# GD32F5xx register map
File version: 1.0
CPU: CM33 r0p1, little endian, MPU, FPU, 4 interrupt priority bits
Registers are 32-bit, read-write, reset 0x0 unless marked. A register's access mark holds for its fields unless they carry their own. Offsets are from the block's base; [hi:lo] are bit positions; 'fields as' and 'values as' point back to an identical list.

## IREF — Programmable current reference
Base 0x4000C400
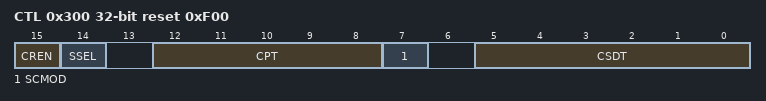
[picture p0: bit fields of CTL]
0x300 CTL reset 0xF00 — Control register
  [15] CREN — Current reference enable
  [14] SSEL — Step selection
  [12:8] CPT — Current precision trim for output current offset
  [7] SCMOD — Sink current mode
  [5:0] CSDT — Current step data

## PKCAU — Public Key Cryptographic Acceleration Unit
Base 0x50061000
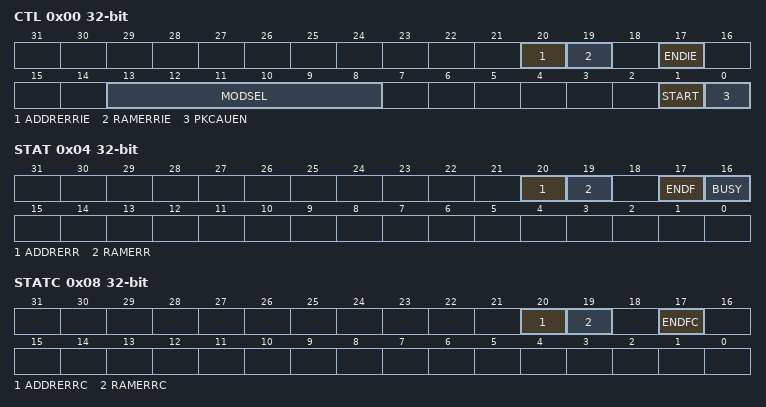
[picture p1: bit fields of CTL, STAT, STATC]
0x00 CTL — Control register
  [20] ADDRERRIE — Address error interrupt enable
  [19] RAMERRIE — RAM error interrupt enable
  [17] ENDIE — End of operation interrupt enable
  [13:8] MODSEL — PKCAU operation mode selection
  [1] START — PKCAU starts operation
  [0] PKCAUEN — PKCAU enable
0x04 STAT ro — Status register
  [20] ADDRERR — Address error.
  [19] RAMERR — PKCAU RAM error
  [17] ENDF — End of PKCAU operation
  [16] BUSY — Busy flag
0x08 STATC wo — Status clear register
  [20] ADDRERRC — Address error flag clear.
  [19] RAMERRC — PKCAU RAM error flag clear.
  [17] ENDFC — End of PKCAU operation flag clear.

## PMU — Power management unit
Base 0x40007000
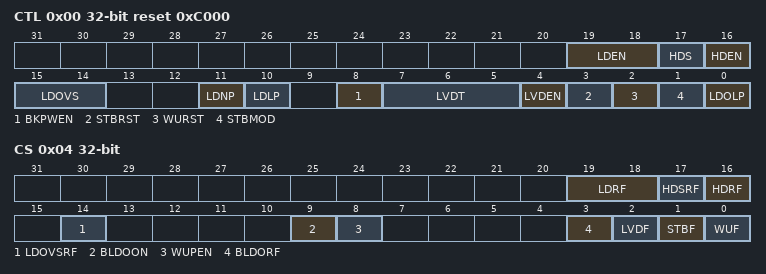
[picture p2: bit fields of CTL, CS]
0x00 CTL reset 0xC000 — Control register
  [19:18] LDEN — Enable low-driver mode in Deep-sleep mode
  [17] HDS — High-driver mode switch
  [16] HDEN — High-driver mode enable
  [15:14] LDOVS — LDO output voltage select
  [11] LDNP — Low-driver mode when use normal power LDO
  [10] LDLP — Low-driver mode when use low power LDO.
  [8] BKPWEN — Backup domain write enable
  [7:5] LVDT — Low voltage detector threshold
  [4] LVDEN — Low voltage detector enable
  [3] STBRST — Standby flag reset
  [2] WURST — Wakeup flag reset
  [1] STBMOD — Standby mode
  [0] LDOLP — LDO low power Mode
0x04 CS access per field — Control and status register
  [19:18] LDRF rw — Low-driver mode ready flag
  [17] HDSRF ro — High-driver switch ready flag
  [16] HDRF ro — High-driver ready flag
  [14] LDOVSRF ro — LDO voltage select ready flag
  [9] BLDOON rw — Backup SRAM LDO on
  [8] WUPEN rw — WKUP Pin (PA0) enable
  [3] BLDORF ro — Backup SRAM LDO ready flag
  [2] LVDF ro — Low voltage detector status flag
  [1] STBF ro — Standby flag
  [0] WUF ro — Wakeup flag

## SAI — Serial Audio Interface
Base 0x40015800
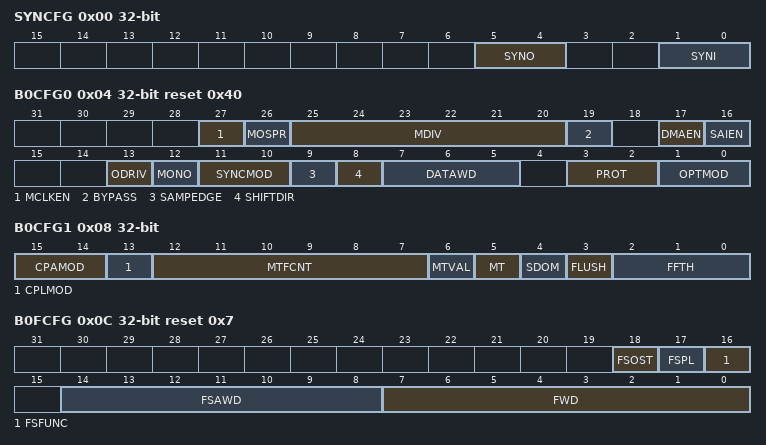
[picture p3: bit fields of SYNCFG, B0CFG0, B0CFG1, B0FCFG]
0x00 SYNCFG — Synchronize configuration register
  [5:4] SYNO — Synchronization outputs
  [1:0] SYNI — Synchronization inputs.
0x04 B0CFG0 reset 0x40 — Block 0 configuration registe
  [27] MCLKEN — The master clock enable
  [26] MOSPR — The master clock oversampling rate.
  [25:20] MDIV — Master clock divider ratio.
  [19] BYPASS — Clock divider logic bypass.
  [17] DMAEN — DMA enable.
  [16] SAIEN — SAI sub-block enable.
  [13] ODRIV — Output Drive.
  [12] MONO — Stereo and Mono mode selection.
  [11:10] SYNCMOD — Synchronization mode.
  [9] SAMPEDGE — Sampling clock edge.
  [8] SHIFTDIR — Shift direction.
  [7:5] DATAWD — Data width.
  [3:2] PROT — Protocol selection.
  [1:0] OPTMOD — Operating mode.
0x08 B0CFG1 — Block 0 configuration registe
  [15:14] CPAMOD — Compander mode.
  [13] CPLMOD — Complement mode.
  [12:7] MTFCNT — Mute frame count.
  [6] MTVAL — Mute value.
  [5] MT — Mute.
  [4] SDOM — Serial data output management.
  [3] FLUSH — FIFO flush.
  [2:0] FFTH — FIFO threshold.
0x0C B0FCFG reset 0x7 — Block 0 frame configuration regist
  [18] FSOST — Frame synchronization offset.
  [17] FSPL — Frame synchronization active polarity.
  [16] FSFUNC — Frame synchronization function.
  [14:8] FSAWD — Frame synchronization active width.
  [7:0] FWD — Frame width
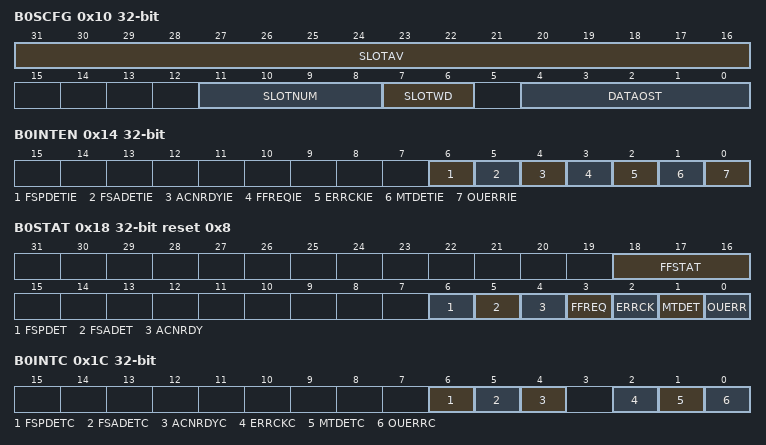
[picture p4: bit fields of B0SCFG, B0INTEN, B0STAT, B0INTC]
0x10 B0SCFG — Block 0 slot configuration regist
  [31:16] SLOTAV — Slot activation vector.
  [11:8] SLOTNUM — Slot number within frame.
  [7:6] SLOTWD — Slot width.
  [4:0] DATAOST — Data offset.
0x14 B0INTEN — Block 0 interrupt enable regist
  [6] FSPDETIE — Frame synchronization postpone detection interrupt enable.
  [5] FSADETIE — Frame synchronization advanced detection interrupt enable.
  [4] ACNRDYIE — Audio codec not ready interrupt enable.
  [3] FFREQIE — FIFO request interrupt enable.
  [2] ERRCKIE — Error clock interrupt enable. It is set and cleared by software.
  [1] MTDETIE — Mute detection interrupt enable.
  [0] OUERRIE — FIFO overrun or underrun interrupt enable.
0x18 B0STAT ro reset 0x8 — Block 0 status regist
  [18:16] FFSTAT — FIFO status.
  [6] FSPDET — Frame synchronization postponed detection.
  [5] FSADET — Frame synchronization advanced detection.
  [4] ACNRDY — Audio codec not ready.
  [3] FFREQ — FIFO request
  [2] ERRCK — Error clock.
  [1] MTDET — Mute detection.
  [0] OUERR — Overrun or underrun.
0x1C B0INTC — Block 0 interrupt flag clear regist
  [6] FSPDETC — Frame synchronization postponed detection interrupt clear.
  [5] FSADETC — Frame synchronization advanced detection interrupt clear.
  [4] ACNRDYC — Audio codec not ready interrupt clear.
  [2] ERRCKC — Clock error interrupt clear.
  [1] MTDETC — Mute detection interrupt clear.
  [0] OUERRC — Overrun or underrun interrupt clear.
0x20 B0DATA — Block 0 data regist
  [31:0] DATA
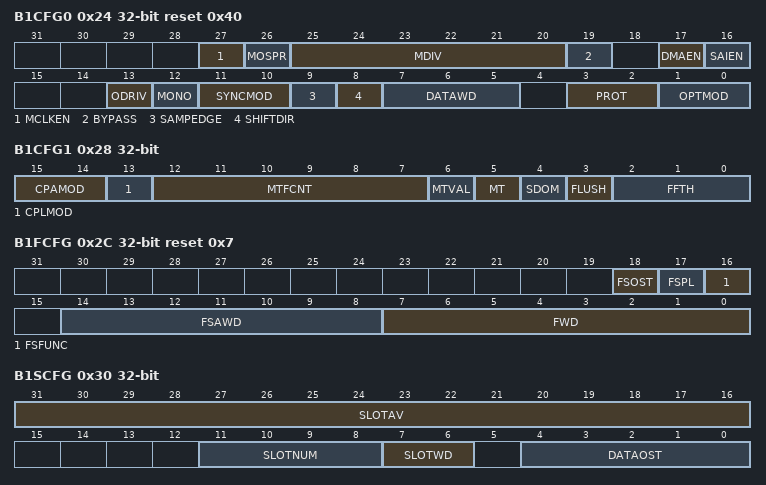
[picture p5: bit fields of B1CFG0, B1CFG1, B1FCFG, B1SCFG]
0x24 B1CFG0 reset 0x40 — Block 1 configuration registe
  fields as B0CFG0
0x28 B1CFG1 — Block 1 configuration registe
  fields as B0CFG1
0x2C B1FCFG reset 0x7 — Block 1 frame configuration regist
  fields as B0FCFG
0x30 B1SCFG — Block 1 slot configuration regist
  fields as B0SCFG
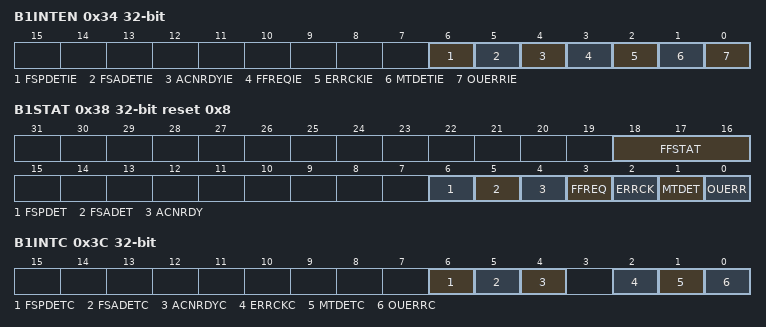
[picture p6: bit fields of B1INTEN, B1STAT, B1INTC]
0x34 B1INTEN — Block 1 interrupt enable regist
  fields as B0INTEN
0x38 B1STAT ro reset 0x8 — Block 1 status regist
  fields as B0STAT
0x3C B1INTC — Block 1 interrupt flag clear regist
  fields as B0INTC
0x40 B1DATA — Block 1 data regist
  [31:0] DATA
